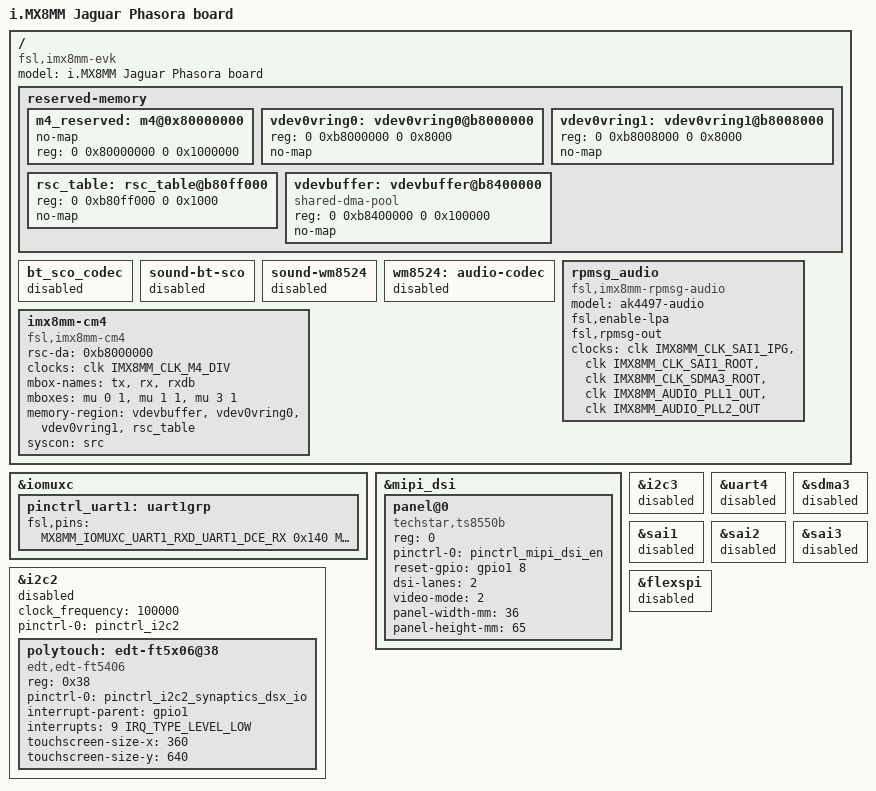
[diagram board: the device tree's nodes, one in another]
// SPDX-License-Identifier: (GPL-2.0+ OR MIT)
/*
 * Copyright 2019 NXP
 */

#include "freescale/imx8mm-evkb.dts"
#include <dt-bindings/gpio/gpio.h>
#include <dt-bindings/leds/common.h>

/ {
	model = "i.MX8MM Jaguar Phasora board";
	compatible = "fsl,imx8mm-evk", "fsl,imx8mm";

	reserved-memory {
		#address-cells = <2>;
		#size-cells = <2>;
		ranges;

		m4_reserved: m4@0x80000000 {
			no-map;
			reg = <0 0x80000000 0 0x1000000>;
		};

		vdev0vring0: vdev0vring0@b8000000 {
			reg = <0 0xb8000000 0 0x8000>;
			no-map;
		};

		vdev0vring1: vdev0vring1@b8008000 {
			reg = <0 0xb8008000 0 0x8000>;
			no-map;
		};

		rsc_table: rsc_table@b80ff000 {
			reg = <0 0xb80ff000 0 0x1000>;
			no-map;
		};

		vdevbuffer: vdevbuffer@b8400000 {
			compatible = "shared-dma-pool";
			reg = <0 0xb8400000 0 0x100000>;
			no-map;
		};
	};

	bt_sco_codec: bt_sco_codec {
		status = "disabled";
	};

	sound-bt-sco {
		status = "disabled";
	};

	sound-wm8524 {
		status = "disabled";
	};

	wm8524: audio-codec {
		status = "disabled";
	};

	rpmsg_audio: rpmsg_audio {
		compatible = "fsl,imx8mm-rpmsg-audio";
		model = "ak4497-audio";
		fsl,enable-lpa;
		fsl,rpmsg-out;
		clocks = <&clk IMX8MM_CLK_SAI1_IPG>,
			 <&clk IMX8MM_CLK_SAI1_ROOT>,
			 <&clk IMX8MM_CLK_SDMA3_ROOT>,
			 <&clk IMX8MM_AUDIO_PLL1_OUT>,
			 <&clk IMX8MM_AUDIO_PLL2_OUT>;
		clock-names = "ipg", "mclk", "dma", "pll8k", "pll11k";
		status = "okay";
	};

	imx8mm-cm4 {
		compatible = "fsl,imx8mm-cm4";
		rsc-da = <0xb8000000>;
		clocks = <&clk IMX8MM_CLK_M4_DIV>;
		mbox-names = "tx", "rx", "rxdb";
		mboxes = <&mu 0 1
			  &mu 1 1
			  &mu 3 1>;
		memory-region = <&vdevbuffer>, <&vdev0vring0>, <&vdev0vring1>, <&rsc_table>;
		syscon = <&src>;
	};
};

&iomuxc {
	pinctrl_uart1: uart1grp {
		fsl,pins = <
			MX8MM_IOMUXC_UART1_RXD_UART1_DCE_RX     0x140
			MX8MM_IOMUXC_UART1_TXD_UART1_DCE_TX     0x140
			MX8MM_IOMUXC_UART3_RXD_UART1_DCE_CTS_B  0x140
			MX8MM_IOMUXC_UART3_TXD_UART1_DCE_RTS_B  0x140
			MX8MM_IOMUXC_SD1_DATA4_GPIO2_IO6        0x19
		>;
	};
};

//&uart1 { /* BT */
//	bluetooth {
//		compatible = "qcom,qca9377-bt";
//		enable-gpios = <&gpio2 6 GPIO_ACTIVE_HIGH>;
//              status = "disabled";
//	};
//};

&mipi_dsi {

        panel@0 {
                compatible = "techstar,ts8550b";
                reg = <0>;
                pinctrl-0 = <&pinctrl_mipi_dsi_en>;
                reset-gpio = <&gpio1 8 GPIO_ACTIVE_HIGH>;
                dsi-lanes = <2>;
                video-mode = <2>;       /* 0: burst mode
                                         * 1: non-burst mode with sync event
                                         * 2: non-burst mode with sync pulse
                                         * 3: command mode
                                         */
                panel-width-mm = <36>;
                panel-height-mm = <65>;
                status = "okay";
        };
};

&i2c2 { 
        clock_frequency = <100000>;
        pinctrl-names = "default";
        pinctrl-0 = <&pinctrl_i2c2>;
        status = "okay";

	/delete-node/ hdmi;

        polytouch: edt-ft5x06@38 {
                compatible = "edt,edt-ft5406", "edt,edt-ft5x06";
                reg = <0x38>;
                pinctrl-names = "default";
                pinctrl-0 = <&pinctrl_i2c2_synaptics_dsx_io>;
                interrupt-parent = <&gpio1>;
                interrupts = <9 IRQ_TYPE_LEVEL_LOW>;

                touchscreen-size-x = <360>;
                touchscreen-size-y = <640>;
        };

       status = "disabled";
};

&i2c3 {
	status = "disabled";
};

/*
 * ATTENTION: M4 may use IPs like below
 * ECSPI0/ECSPI2, GPIO1/GPIO5, GPT1, I2C3, I2S3, WDOG1, UART4, PWM3, SDMA1
 */

&uart4 {
	status = "disabled";
};

&sdma3 {
	status = "disabled";
};

&sai1 {
	status = "disabled";
};

&sai2 {
	status = "disabled";
};

&sai3 {
	status = "disabled";
};

&flexspi {
	status = "disabled";
};
